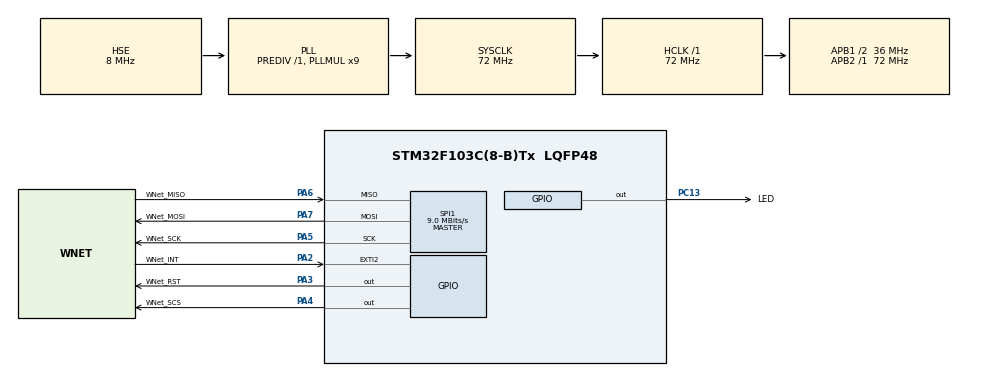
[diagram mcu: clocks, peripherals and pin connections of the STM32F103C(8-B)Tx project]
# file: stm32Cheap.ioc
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Mcu.Family=STM32F1
Mcu.Name=STM32F103C(8-B)Tx
Mcu.Package=LQFP48
NVIC.EXTI2_IRQn=true\:0\:0\:false\:true\:true\:1\:true\:true
NVIC.PriorityGroup=NVIC_PRIORITYGROUP_2
NVIC.TIM2_IRQn=true\:0\:0\:false\:false\:true\:true\:true
PA13.Mode=Serial_Wire
PA13.Signal=SYS_JTMS-SWDIO
PA14.Mode=Serial_Wire
PA14.Signal=SYS_JTCK-SWCLK
PA2.GPIO_Label=WNet_INT
PA2.GPIO_ModeDefaultEXTI=GPIO_MODE_IT_FALLING
PA2.GPIO_PuPd=GPIO_PULLUP
PA2.Signal=GPXTI2
PA3.GPIO_Label=WNet_RST
PA3.GPIO_Speed=GPIO_SPEED_FREQ_LOW
PA3.Signal=GPIO_Output
PA4.GPIO_Label=WNet_SCS
PA4.GPIO_Speed=GPIO_SPEED_FREQ_MEDIUM
PA4.Signal=GPIO_Output
PA5.GPIO_Label=WNet_SCK
PA5.Mode=Full_Duplex_Master
PA5.Signal=SPI1_SCK
PA6.GPIO_Label=WNet_MISO
PA6.Mode=Full_Duplex_Master
PA6.Signal=SPI1_MISO
PA7.GPIO_Label=WNet_MOSI
PA7.Mode=Full_Duplex_Master
PA7.Signal=SPI1_MOSI
PC13-TAMPER-RTC.GPIO_Label=LED
PC13-TAMPER-RTC.Signal=GPIO_Output
PC14-OSC32_IN.Signal=RCC_OSC32_IN
PC15-OSC32_OUT.Signal=RCC_OSC32_OUT
PD0-OSC_IN.Mode=HSE-External-Oscillator
PD0-OSC_IN.Signal=RCC_OSC_IN
PD1-OSC_OUT.Mode=HSE-External-Oscillator
PD1-OSC_OUT.Signal=RCC_OSC_OUT
ProjectManager.HeapSize=0x200
ProjectManager.StackSize=0x400
ProjectManager.TargetToolchain=SW4STM32
RCC.AHBFreq_Value=72000000
RCC.APB1CLKDivider=RCC_HCLK_DIV2
RCC.APB1Freq_Value=36000000
RCC.APB1TimFreq_Value=72000000
RCC.APB2Freq_Value=72000000
RCC.APB2TimFreq_Value=72000000
RCC.HCLKFreq_Value=72000000
RCC.PLLMUL=RCC_PLL_MUL9
RCC.PLLSourceVirtual=RCC_PLLSOURCE_HSE
RCC.SYSCLKFreq_VALUE=72000000
RCC.SYSCLKSource=RCC_SYSCLKSOURCE_PLLCLK
RCC.USBFreq_Value=72000000
SPI1.BaudRatePrescaler=SPI_BAUDRATEPRESCALER_8
SPI1.CalculateBaudRate=9.0 MBits/s
SPI1.Direction=SPI_DIRECTION_2LINES
SPI1.FirstBit=SPI_FIRSTBIT_MSB
SPI1.Mode=SPI_MODE_MASTER
SPI1.VirtualType=VM_MASTER
TIM2.Period=9
TIM2.Prescaler=7199
VP_TIM2_VS_ClockSourceINT.Mode=Internal
board=custom

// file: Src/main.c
/* USER CODE BEGIN Header */
/**
  ******************************************************************************
  * @file           : main.c
  * @brief          : Main program body
  ******************************************************************************
  * @attention
  *
  * <h2><center>&copy; Copyright (c) 2019 STMicroelectronics.
  * All rights reserved.</center></h2>
  *
  * This software component is licensed by ST under BSD 3-Clause license,
  * the "License"; You may not use this file except in compliance with the
  * License. You may obtain a copy of the License at:
  *                        opensource.org/licenses/BSD-3-Clause
  *
  ******************************************************************************
  */
/* USER CODE END Header */

#include "main.h"
#include "spi.h"
#include "tim.h"
#include "gpio.h"

/* USER CODE BEGIN Includes */
#include "WOLInterface.h"
/* USER CODE END Includes */

void SystemClock_Config(void);
static void MX_NVIC_Init(void);

/* USER CODE BEGIN 0 */
int GlobalFlag = 0;

void HAL_GPIO_EXTI_Callback(uint16_t GPIO_Pin){
    GlobalFlag = 1;
//    for (int i = 0; i < 100; ++i) {
//    }
}
/* USER CODE END 0 */

int main(void)
{

  /* MCU Configuration--------------------------------------------------------*/

  /* Reset of all peripherals, Initializes the Flash interface and the Systick. */
  HAL_Init();

  /* Configure the system clock */
  SystemClock_Config();

  /* Initialize all configured peripherals */
  MX_GPIO_Init();
  MX_SPI1_Init();
  MX_TIM2_Init();

  /* Initialize interrupts */
  MX_NVIC_Init();

  /* Infinite loop */
  while (1)
  {

    /* USER CODE BEGIN 3 */
    if(!RunCode()){
        break;
    }
  }
  /* USER CODE END 3 */
}

void SystemClock_Config(void)
{
  RCC_OscInitTypeDef RCC_OscInitStruct = {0};
  RCC_ClkInitTypeDef RCC_ClkInitStruct = {0};

  /** Initializes the CPU, AHB and APB busses clocks
  */
  RCC_OscInitStruct.OscillatorType = RCC_OSCILLATORTYPE_HSE;
  RCC_OscInitStruct.HSEState = RCC_HSE_ON;
  RCC_OscInitStruct.HSEPredivValue = RCC_HSE_PREDIV_DIV1;
  RCC_OscInitStruct.HSIState = RCC_HSI_ON;
  RCC_OscInitStruct.PLL.PLLState = RCC_PLL_ON;
  RCC_OscInitStruct.PLL.PLLSource = RCC_PLLSOURCE_HSE;
  RCC_OscInitStruct.PLL.PLLMUL = RCC_PLL_MUL9;
  if (HAL_RCC_OscConfig(&RCC_OscInitStruct) != HAL_OK)
  {
    Error_Handler();
  }
  /** Initializes the CPU, AHB and APB busses clocks
  */
  RCC_ClkInitStruct.ClockType = RCC_CLOCKTYPE_HCLK|RCC_CLOCKTYPE_SYSCLK
                              |RCC_CLOCKTYPE_PCLK1|RCC_CLOCKTYPE_PCLK2;
  RCC_ClkInitStruct.SYSCLKSource = RCC_SYSCLKSOURCE_PLLCLK;
  RCC_ClkInitStruct.AHBCLKDivider = RCC_SYSCLK_DIV1;
  RCC_ClkInitStruct.APB1CLKDivider = RCC_HCLK_DIV2;
  RCC_ClkInitStruct.APB2CLKDivider = RCC_HCLK_DIV1;

  if (HAL_RCC_ClockConfig(&RCC_ClkInitStruct, FLASH_LATENCY_2) != HAL_OK)
  {
    Error_Handler();
  }
}

/**
  * @brief NVIC Configuration.
  * @retval None
  */
static void MX_NVIC_Init(void)
{
  /* EXTI2_IRQn interrupt configuration */
  HAL_NVIC_SetPriority(EXTI2_IRQn, 0, 0);
  HAL_NVIC_EnableIRQ(EXTI2_IRQn);
}

void Error_Handler(void)
{
}

/************************ (C) COPYRIGHT STMicroelectronics *****END OF FILE****/
